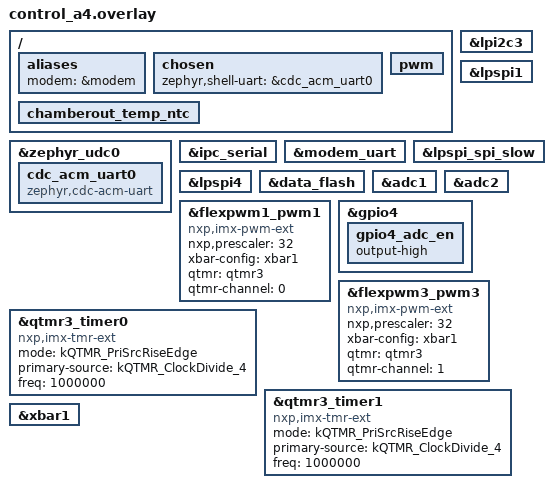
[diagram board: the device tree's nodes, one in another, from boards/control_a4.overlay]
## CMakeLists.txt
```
cmake_minimum_required(VERSION 3.25)

# Must be before find_package(Zephyr) to provide custom board and shield specifications
include(${CMAKE_CURRENT_SOURCE_DIR}/../CMakeFiles/globals.cmake)
include(${CMAKE_CURRENT_SOURCE_DIR}/../CMakeFiles/shields.cmake)

if(NOT DEFINED ENV{ZEPHYR_BASE})
    set(ZEPHYR_BASE ${ZEPHYR_ABS_DIR} CACHE PATH "The directory points to Zephyr root" FORCE)
else()
    set(ZEPHYR_BASE $ENV{ZEPHYR_BASE} CACHE PATH "The directory points to Zephyr root" FORCE)
endif()

if(DEFINED EXTRA_CONF_FILE)
  set(_extra_conf_file_candidates ${EXTRA_CONF_FILE})
  set(_extra_conf_file_existing)

  foreach(_extra_conf_file IN LISTS _extra_conf_file_candidates)
    if(IS_ABSOLUTE "${_extra_conf_file}")
      set(_extra_conf_file_path "${_extra_conf_file}")
    else()
      set(_extra_conf_file_path "${CMAKE_CURRENT_SOURCE_DIR}/${_extra_conf_file}")
    endif()

    if(EXISTS "${_extra_conf_file_path}")
      list(APPEND _extra_conf_file_existing "${_extra_conf_file}")
    else()
      message(STATUS "Skipping missing optional EXTRA_CONF_FILE entry: ${_extra_conf_file}")
    endif()
  endforeach()

  if(_extra_conf_file_existing)
    set(EXTRA_CONF_FILE "${_extra_conf_file_existing}" CACHE STRING "Existing extra configuration files" FORCE)
  else()
    unset(EXTRA_CONF_FILE CACHE)
    unset(EXTRA_CONF_FILE)
  endif()

  unset(_extra_conf_file_candidates)
  unset(_extra_conf_file_existing)
  unset(_extra_conf_file)
  unset(_extra_conf_file_path)
endif()

# Find zephyr and import Zephyr's cmake
find_package(Zephyr REQUIRED HINTS ${ZEPHYR_BASE})

project(control_application)

include(${CMAKE_CURRENT_SOURCE_DIR}/../CMakeFiles/firmware-compile-options.cmake)
include(${PLATFORM_DIR}/CMakeFiles/build-platform-targets.cmake) # Discover all all targets under platform directory.

target_sources(app PRIVATE
  ${CONTROL_SRC_DIR}/main.c
)

generate_inc_file_for_target(
    app
    ${CMAKE_CURRENT_SOURCE_DIR}/one_month.txt
    one_month_txt.inc
)

# Platform units
target_link_libraries(app PRIVATE platform_src_modem_board_obj)
target_link_libraries(app PRIVATE platform_src_modem_at_obj)
target_link_libraries(app PRIVATE platform_src_modem_rc7620_obj)
target_link_libraries(app PRIVATE platform_src_modem_link_obj)
target_link_libraries(app PRIVATE platform_src_modem_shell_obj)

mark_zephyr_system_includes(app)
target_link_libraries(app PRIVATE zephyr_interface)
add_dependencies(app zephyr_generated_headers)
```

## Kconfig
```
source "Kconfig.zephyr"

rsource "../common/Kconfig"

menu "Control application"

config CONTROL_APN
	string "PPP APN"
	default ""
	help
	  APN used by the custom modem PPP shell helpers.

config CONTROL_APN_USERNAME
	string "PPP APN username"
	default ""
	help
	  Optional username used by the custom modem PPP shell helpers.

config CONTROL_APN_PASSWORD
	string "PPP APN password"
	default ""
	help
	  Optional password used by the custom modem PPP shell helpers.

config CONTROL_SERVER_HOST
	string "Verified HTTPS server hostname"
	default ""
	help
	  DNS hostname used for TLS SNI, DNS lookup, and the HTTP Host header
	  when the control application sends its HTTPS upload request.

config CONTROL_SERVER_URL
	string "HTTPS server URL path"
	default "/gus.asmx/dev"
	help
	  HTTP target path used by the control application upload request.

config CONTROL_SERVER_PORT
	int "HTTPS server TCP port"
	range 1 65535
	default 443
	help
	  TCP port used by the control application upload request.

config CONTROL_TLS_SERVER_CA_CERT_PEM
	string "HTTPS POST root CA certificate"
	depends on NET_SOCKETS_SOCKOPT_TLS
	default ""
	help
	  PEM-encoded root CA certificate used by the control application HTTPS
	  upload request. Keep the local-only value in control/prj.secrets.conf
	  and encode line breaks with escaped newlines.

endmenu
```

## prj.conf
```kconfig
#
# Specify project wide configuration of Zephyr for Waitara Control application.
#
# For detailed documentation of Zephyr configuration options, see:
#    https://docs.zephyrproject.org/3.5.0/kconfig.html
# (Ensure version of Zephyr selected matches what is currently in use
#  on project)
#

#
# Select features of Zephyr to be used, these are then further configured in sections below\
#
### Zephyr feature selection ###

CONFIG_CMSIS_RTOS_V2=y                # Use V2 of CMSIS RTOS API required by pRTOS implementation
CONFIG_CONSOLE=y
CONFIG_PICOLIBC=y                     # Use picolibc as C standard library
CONFIG_POLL=y                         # Enable Asynchronous notification framework used in pRTOS

CONFIG_STDOUT_CONSOLE=n               # Redirect STDOUT to a console until proper logging is in place

# Other / Floating Point Services
CONFIG_FPU=y          # Let Zephyr be floating point aware. See https://gitlab.fphcare.com/cpap-software/waitara/waitara/-/issues/432 for additional info
CONFIG_FPU_SHARING=y  # Multiple threads will use floating point operations.


# Custom Linker script 
CONFIG_HAVE_CUSTOM_LINKER_SCRIPT=y # Ensure image is even sized for bootloader 
CONFIG_CUSTOM_LINKER_SCRIPT="linker-script.ld"

### /Zephyr feature selection ###

# Keep RTT log/console enabled (logs on RTT, shell on USB)
CONFIG_USE_SEGGER_RTT=y
CONFIG_SEGGER_RTT_SECTION_NONE=y
CONFIG_RTT_CONSOLE=y
CONFIG_LOG_BACKEND_RTT=y

# Shell over USB CDC ACM
CONFIG_SHELL=y
CONFIG_SHELL_BACKEND_SERIAL=y
CONFIG_SHELL_LOG_BACKEND=n              # Needed to prevent logs from being sent to the shell backend
CONFIG_KERNEL_SHELL=y
CONFIG_SHELL_STACK_SIZE=8192

# USB device stack / CDC ACM
CONFIG_USB_DEVICE_STACK=y
CONFIG_USB_CDC_ACM=y
CONFIG_UART_LINE_CTRL=y
CONFIG_UART_INTERRUPT_DRIVEN=y
CONFIG_USB_DEVICE_INITIALIZE_AT_BOOT=y

# Ensure we can drive board-level USB power enable pins early
CONFIG_GPIO=y
CONFIG_ADC=y

# USB identity
CONFIG_USB_DEVICE_VID=0x2FE3
CONFIG_USB_DEVICE_PID=0x0100
CONFIG_USB_DEVICE_PRODUCT="Modem Control Shell"
CONFIG_USB_DEVICE_MANUFACTURER="FPH"
CONFIG_USB_DEVICE_SN="0000001"

# USB diagnostic logging (enable during bring-up; reduce to WARNING after stable)
CONFIG_USB_DEVICE_LOG_LEVEL_WRN=y
CONFIG_USB_CDC_ACM_LOG_LEVEL_WRN=y

# Use the platform-local RC7620 modem stack.
CONFIG_MODEM=y
CONFIG_MODEM_RC7620=y
CONFIG_PM_DEVICE=y

# Defang periodic AT polling to reduce CMUX contention during PPP data bursts
CONFIG_MODEM_RC7620_PERIODIC_SCRIPT_MS=600000
CONFIG_MODEM_LOG_LEVEL_DBG=n
CONFIG_MODEM_MODULES_LOG_LEVEL_DBG=n
CONFIG_MODEM_CMUX_LOG_LEVEL_DBG=n
CONFIG_MODEM_RC7620_UART_BUFFER_SIZE=2048
CONFIG_MODEM_CMUX_MTU=31
CONFIG_MODEM_CMUX_WORK_BUFFER_SIZE=38
# ISR idle timeout: (UART_BUF/2)/(baud/10)*1000 = (2048/2)/(115200/10)*1000 = 89 ms
CONFIG_MODEM_BACKEND_UART_ISR_RECEIVE_IDLE_TIMEOUT_MS=89

# PPP + networking stack for modem HTTPS POST command
CONFIG_NETWORKING=y
CONFIG_NET_NATIVE=y
CONFIG_NET_L2_PPP=y
CONFIG_NET_L2_PPP_MGMT=y
CONFIG_NET_L2_PPP_OPTION_DNS_USE=y
CONFIG_NET_IPV4=y
CONFIG_NET_IPV6=n
CONFIG_NET_TCP=y
CONFIG_NET_UDP=y
CONFIG_NET_SOCKETS=y
CONFIG_NET_SOCKETS_LOG_LEVEL_DBG=y
CONFIG_POSIX_API=y
CONFIG_DNS_RESOLVER=y
CONFIG_DNS_RESOLVER_LOG_LEVEL_DBG=y
CONFIG_NET_SOCKETS_DNS_TIMEOUT=15000
CONFIG_DNS_RESOLVER_MAX_SERVERS=2
CONFIG_DNS_SERVER_IP_ADDRESSES=y
CONFIG_NET_MGMT=y
CONFIG_NET_MGMT_EVENT=y
CONFIG_NET_CONNECTION_MANAGER=y
CONFIG_NET_L2_PPP_LOG_LEVEL_DBG=y
CONFIG_NET_TX_STACK_SIZE=4096
CONFIG_NET_RX_STACK_SIZE=4096
CONFIG_ZVFS_OPEN_MAX=8
CONFIG_NET_MAX_CONTEXTS=12
CONFIG_NET_SOCKETS_TLS_MAX_CONTEXTS=4

# Network packet buffer pool - default of 4 RX pkts is too low for PPP+DNS
# Match Ethernet default; prevents pool exhaustion during DNS + PPP traffic
CONFIG_NET_PKT_TX_COUNT=16
CONFIG_NET_BUF_TX_COUNT=64
CONFIG_NET_PKT_RX_COUNT=14
# 28 x 128 bytes = 3.5 KB; covers fragmented PPP frames
CONFIG_NET_BUF_RX_COUNT=28
# Keep the TCP send window inside the TX fragment pool used by the known-good upload config.
CONFIG_NET_TCP_MAX_SEND_WINDOW_SIZE=5440
CONFIG_NET_TCP_PKT_ALLOC_TIMEOUT=500

# HTTP client + TLS socket support
CONFIG_HTTP_CLIENT=y
CONFIG_NET_SOCKETS_SOCKOPT_TLS=y

CONFIG_CRYPTO=y
CONFIG_TLS_CREDENTIALS=y
CONFIG_NET_SOCKETS_SOCKOPT_TLS=y
CONFIG_MBEDTLS_PEM_CERTIFICATE_FORMAT=y
CONFIG_MBEDTLS_DEBUG=y

# Buffer/workqueue sizing
CONFIG_USB_CDC_ACM_RINGBUF_SIZE=2048
# Keep the system workqueue responsive during USB IO
# Priority 0 = highest preemptive; prevents CMUX/PPP workqueue starvation
CONFIG_SYSTEM_WORKQUEUE_PRIORITY=3
# 4 KB stack for modem/networking workqueue tasks
CONFIG_SYSTEM_WORKQUEUE_STACK_SIZE=4096
### / Temp for Devboard to P2 board bringup ###

####  RTOS Configuration ###
CONFIG_MAIN_STACK_SIZE=8192
                                        # Match the known-good upload config for HTTPS/TLS request handling and logging
CONFIG_THREAD_NAME=y                    # Allow tracing to display thread name for debugging
CONFIG_THREAD_STACK_INFO=y              # Allow each thread to store thread stack info in k_thread data structure
CONFIG_THREAD_MONITOR=y                 # Instruct kernel to maintain a list of all threads for debugging
CONFIG_THREAD_RUNTIME_STATS=y           # Gather thread runtime statistics. For example: Thread total execution cycles, System total execution cycles. Used for monitoring of scheduler performance
CONFIG_SCHED_THREAD_USAGE=y             # Collect thread runtime usage. Used for monitoring of scheduler performance
CONFIG_INIT_STACKS=y                    # Initialise stacks with a known value so that high water mark can be determined for debugging
                                        # Init value: 0xAA
CONFIG_NUM_COOP_PRIORITIES=2
                                        # Match the known-good upload config used for HTTP client uploads.
CONFIG_PRIORITY_CEILING=0
                                        # If cooperative task is disabled, ceiling priority should be 0, not -127(default)

CONFIG_SYS_CLOCK_TICKS_PER_SEC=10000
                                        # Using value greater than default to increase precision in delays
CONFIG_NUM_PREEMPT_PRIORITIES=56
                                        # Max priority in CMSIS v2. osPriority_t
CONFIG_USERSPACE=n                      # This option ennable threads in user mode to protect kernel
                                        # In current implementation, CMSIS v2 doesn't support options.
CONFIG_HW_STACK_PROTECTION=y            # Catch stack overflows when in privileged mode
CONFIG_STACK_CANARIES=y                 # Inserts a canary value into the stack frame when a function is entered and validates this value upon exit
                                        # Decrease performance. Only for initial state of project.
CONFIG_STACK_CANARIES_ALL=y             # equivalent to GCC option `-fstack-protector-all`
CONFIG_ENTROPY_GENERATOR=y              # CONFIG_STACK_CANARIES dependent option. Used to generate random number for Canary value
CONFIG_NUM_MBOX_ASYNC_MSGS=10
                                        # Default: 10, the total number of asynchronous mailbox messages that can exist simultaneously                                         

# Configuring timeslice size to 1 allows threads on same priority to get execution time every 1 ms. This is
# needed for:
#   - usb_mcx & usbworkq - dependency of device data.
CONFIG_TIMESLICING=y
CONFIG_TIMESLICE_SIZE=1

####  /RTOS Configuration ###

#### CMSIS Configuration ###
CONFIG_CMSIS_V2_THREAD_MAX_STACK_SIZE=8192
                                            # FIXME: Did not think this was required but removing results in run time assertion on dev board
CONFIG_CMSIS_V2_THREAD_DYNAMIC_MAX_COUNT=0
                                            # Define static memory size for dynamic thread in CMSIS
CONFIG_CMSIS_V2_MSGQ_MAX_DYNAMIC_SIZE=0
                                            # Don't allow CMSIS dynamic queues as it violates coding standard

#####
## Following max count is for static memory allocation for OS service in CMSIS V2
## Thread : Only for the number of TCB. Task stack is allocated in Application.
## Queue  : App allocates memory for message and message queue object is allocated from static memory.
## Timer, Mutex, Semaphore, Event : Static memory allocated in CMSIS for these service.
## Memory pool: Fixed size heap. Not needed.
## NOTE : Slap memory internally used in Zephyr is a kind of dynamic memory, but it should be an exception
##        of coding standard. This is an essential feature in zephyr for OS service, such as Queue, Timer,
##        Mutex, Semaphore and Event etc.
####
CONFIG_CMSIS_V2_THREAD_MAX_COUNT=10
                                            # Maximum number of threads, arbitrary value >= current usage
CONFIG_CMSIS_V2_TIMER_MAX_COUNT=10
                                            # Maximum number of timers, arbitrary value >= current usage
CONFIG_CMSIS_V2_EVT_FLAGS_MAX_COUNT=10
                                            # Default: 5, Need to be adjusted later
CONFIG_CMSIS_V2_MSGQ_MAX_COUNT=10
                                            # Default: 5, Memory for message is allocated by App.
                                            #             Memory for message queue is allocated from static
                                            # This max count define max number of message queue.
CONFIG_CMSIS_V2_MUTEX_MAX_COUNT=100
                                            # Default: 5, Need to be adjusted later
CONFIG_CMSIS_V2_SEMAPHORE_MAX_COUNT=20
                                            # Default: 5, Need to be adjusted later
CONFIG_CMSIS_V2_MEM_SLAB_MAX_COUNT=0
CONFIG_CMSIS_V2_MEM_SLAB_MAX_DYNAMIC_SIZE=0
                                            # Fixed size memory pool(similar to heap). No need for waitara
#### /CMSIS Configuration ###

#### Logging and Assertions ####
CONFIG_LOG=y                                # Compile in Zephyr log calls
# Force to y to ensure log output function pointer is valid from `log_format_func_t_get`. Needed for our custom backends if 
# CONFIG_LOG_BACKEND_RTT is not selected.
CONFIG_LOG_OUTPUT=y
CONFIG_LOG_MODE_DEFERRED=y                  # Enables async logging, i.e. processed later by a thread
CONFIG_LOG_PROCESS_THREAD=y                 # Let Zephyr create the logger thread
CONFIG_LOG_PROCESS_THREAD_STARTUP_DELAY_MS=10000
                                            # Adds delay to logging thread startup. Keeping it 10s to allow enough time
                                            # to connect and stream startup logs to Airvolab/Insight.
CONFIG_LOG_PROCESS_THREAD_STACK_SIZE=3072
CONFIG_LOG_PROCESS_THREAD_SLEEP_MS=10
                                            # Flush/Process logs every 10ms
CONFIG_LOG_PROCESS_TRIGGER_THRESHOLD=10
                                            # Threshold at which the buffered log messages are flushed/processed by logging thread.
                                            # Keeping it 10 (default). Since we have 100ms flush, this is an acceptable value.
CONFIG_LOG_BUFFER_SIZE=4096
                                            # Logging internal buffers that will hold the log messages (Keep it reasonably high to avoid losing messages)
CONFIG_LOG_RUNTIME_FILTERING=y              # Enable ability to change log filter level at runtime
CONFIG_LOG_OVERRIDE_LEVEL=0
                                            # Log override is disabled. Anything higher than 1 will cause MPU fault - Data Access Violation.
CONFIG_ASSERT=y                             # Enable asserts within the kernel
CONFIG_ASSERT_LEVEL=2
                                            # Enable asserts but don't warn on files that include __assert.h
CONFIG_LOG_BACKEND_SHOW_COLOR=n             # Disable colour support to avoid special characters appearing in smarttalk bogs
CONFIG_LOG_MODE_OVERFLOW=y                  # Drop the old messages if there is no space left for a new log message
CONFIG_LOG_DEFAULT_LEVEL=3
                                            # Set default log level to INFO to reduce global debug noise
CONFIG_KERNEL_LOG_LEVEL_WRN=y
                                            # Suppress noisy kernel debug traces like z_tick_sleep in RTT
CONFIG_MPU_LOG_LEVEL_WRN=y
                                            # Suppress repetitive MPU debug region programming traces in RTT
CONFIG_INPUT_LOG_LEVEL_WRN=y
                                            # Suppress gpio_keys periodic poll debug traces in RTT

#### Extras
CONFIG_REBOOT=y                       # Enable sys_reboot() API
CONFIG_BUILD_OUTPUT_HEX=y             # Generate Hex output
CONFIG_STD_C17=y                      # Use C17
CONFIG_COMPILER_OPT=""                # Compiler options for Zephyr kernel and project compilation. ex "-O0 -g3 "
CONFIG_KERNEL_BIN_NAME="control_app"  # Can change the output file name
CONFIG_WARN_DEPRECATED=y              # Print a warning when the Kconfig tree is parsed if any deprecated features are enabled.

CONFIG_FLASH=y
CONFIG_SPI_NOR=y                         # spi nor flash for W25Q128JV, JESD216 compatible
CONFIG_FLASH_MAP=y
CONFIG_SPI_NOR_FLASH_LAYOUT_PAGE_SIZE=4096
                                            # This will be block size(default : 65536)
CONFIG_SPI_LOG_LEVEL_ERR=y              # Only set in order to prevent a bug in spi_nxp_lpspi.c causing compilation warnings 
CONFIG_INPUT=y
CONFIG_INPUT_THREAD_STACK_SIZE=2048

# Allows memory manager to make up to 5 attempts to find a chunk
# of the right size to mitigate potential heap fragmentation
CONFIG_SYS_HEAP_ALLOC_LOOPS=5
```

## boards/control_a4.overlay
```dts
/ {
	aliases {
    modem = &modem;
	};

  chosen {
    zephyr,shell-uart = &cdc_acm_uart0;
  };

  pwm {
    status = "okay";
  };

  chamberout_temp_ntc: chamberout_temp_ntc {
    status = "okay";
  };
};

&zephyr_udc0 {
  status = "okay";

  /* Expose CDC ACM as a UART-like device so shell backend can bind to it. */
  cdc_acm_uart0: cdc_acm_uart0 {
    compatible = "zephyr,cdc-acm-uart";
  };
};

&ipc_serial {
  status = "okay";
};

&modem_uart {
  status = "okay";
};

&lpi2c3 {
  status = "okay";
};

&lpspi1 {
  status = "okay";
};

&lpspi_spi_slow {
  status = "okay";
};

&lpspi4 {
  status = "okay";
};

&data_flash {
  status = "okay";
};

&adc1 {
  status = "okay";
};

&adc2 {
  status = "okay";
};

&flexpwm1_pwm1 {
  compatible = "nxp,imx-pwm-ext";
  status = "okay";

  nxp,prescaler = <32>;
  xbar-config = <&xbar1>;
  // See &qtmr3_timer0 node
  qtmr = <&qtmr3>;
  qtmr-channel = <0>;
};

&qtmr3_timer0 {
  compatible = "nxp,imx-tmr-ext";
  status = "okay";

  mode = "kQTMR_PriSrcRiseEdge";
  primary-source = "kQTMR_ClockDivide_4";
  freq = <1000000>;
};

&gpio4 {
  gpio4_adc_en {
    // Enable ADC isolation for control application
    /delete-property/ output-low;
    output-high;
  };
};

&flexpwm3_pwm3 {
  compatible = "nxp,imx-pwm-ext";
  status = "okay";

  nxp,prescaler = <32>;
  xbar-config = <&xbar1>;
  // See &qtmr3_timer1 node
  qtmr = <&qtmr3>;
  qtmr-channel = <1>;
};

&qtmr3_timer1 {
  compatible = "nxp,imx-tmr-ext";
  status = "okay";

  mode = "kQTMR_PriSrcRiseEdge";
  primary-source = "kQTMR_ClockDivide_4";
  freq = <1000000>;
};

&xbar1 {
  status = "okay";
};
```

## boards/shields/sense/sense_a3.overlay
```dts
/*
 * Copyright (c) Fisher & Paykel Healthcare. All Rights Reserved.
 *
 * Devicetree overlay for Waitara Sense A3 shield for the control board. This overlay enables the nodes
 * relevant for the control application.
 */

#include <zephyr/dt-bindings/input/input-event-codes.h>

/ {
  aliases {
    dt-rtc = &rtc;
  };
};

&lpi2c1 {
  status = "okay";
};

&humidity_sensor {
  status = "okay";
};

&rtc {
  status = "okay";
};

&lpi2c4 {
  status = "okay";
};

&pressure_sensor {
  status = "okay";
};

&lpspi3 {
  status = "okay";
};

&ssd1363 {
  status = "okay";
};

&buttons {
  status = "okay";

  polling-mode;
};

&ui_button_therapy_b {
  zephyr,code = <INPUT_BTN_1>;
};

&ui_button_therapy_a {
  zephyr,code = <INPUT_BTN_2>;
};

&ui_button_down {
  zephyr,code = <INPUT_BTN_3>;
};

&ui_button_up {
  zephyr,code = <INPUT_BTN_4>;
};  

&ui_button_ok {
  zephyr,code = <INPUT_BTN_5>;
};  

&ui_button_menu {
  zephyr,code = <INPUT_BTN_6>;
};  

&longpress {
  input-codes = <INPUT_BTN_2>, 
                <INPUT_BTN_1>,
                <INPUT_BTN_3>,
                <INPUT_BTN_4>, 
                <INPUT_BTN_5>, 
                <INPUT_BTN_6>;
  short-codes = <INPUT_KEY_B>, 
                <INPUT_KEY_A>,
                <INPUT_KEY_C>,
                <INPUT_KEY_D>, 
                <INPUT_KEY_E>, 
                <INPUT_KEY_F>;
  long-codes = <INPUT_KEY_V>, 
               <INPUT_KEY_U>,
               <INPUT_KEY_W>,
               <INPUT_KEY_X>, 
               <INPUT_KEY_Y>, 
               <INPUT_KEY_Z>;
  long-delay-ms = <3000>; // 3 second for long press
};
```

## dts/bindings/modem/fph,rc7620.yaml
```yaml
# SPDX-License-Identifier: Apache-2.0

description: FPH RC7620 modem wired for the Waitara control board

compatible: "fph,rc7620"

include: uart-device.yaml

properties:
  mdm-rail-en-gpios:
    type: phandle-array
    required: true

  mdm-pwr-on-gpios:
    type: phandle-array
    required: true

  mdm-reset-gpios:
    type: phandle-array
    required: true

  auto-start:
    type: boolean

  mdm-power-gpios:
    type: phandle-array

  mdm-wake-gpios:
    type: phandle-array
```

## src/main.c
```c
#include <errno.h>
#include <inttypes.h>
#include <stdio.h>
#include <string.h>

#include <zephyr/autoconf.h>
#include <zephyr/kernel.h>
#include <zephyr/logging/log.h>
#include <zephyr/net/conn_mgr_connectivity.h>
#include <zephyr/net/http/client.h>
#include <zephyr/net/net_event.h>
#include <zephyr/net/net_if.h>
#include <zephyr/net/net_ip.h>
#include <zephyr/net/net_mgmt.h>
#include <zephyr/net/ppp.h>
#include <zephyr/net/socket.h>
#include <zephyr/net/tls_credentials.h>

#include "modem-link.h"
#include "../one_month.h"

LOG_MODULE_REGISTER(control_app, LOG_LEVEL_INF);

#define CONTROL_TLS_SEC_TAG 1
#define CONTROL_HTTP_TIMEOUT_MS (180 * MSEC_PER_SEC)
#define CONTROL_HTTP_CHUNK_SIZE 1024U
#define CONTROL_HTTP_RESPONSE_PREVIEW_LEN 160U
#define CONTROL_PPP_CONNECT_TIMEOUT K_SECONDS(MODEM_LINK_DEFAULT_L4_TIMEOUT_MS / 1000)
#define CONTROL_PPP_DISCONNECT_TIMEOUT K_SECONDS(30)
#define CONTROL_PPP_POLL_INTERVAL K_MSEC(250)

struct control_http_context {
    unsigned int http_status_code;
    bool http_status_logged;
    bool response_complete;
    size_t bytes_sent;
    size_t chunks_sent;
    size_t preview_len;
    char response_preview[CONTROL_HTTP_RESPONSE_PREVIEW_LEN + 1U];
};

static K_SEM_DEFINE(controlAppConnectedSem, 0, 1);
static K_SEM_DEFINE(controlAppDisconnectedSem, 0, 1);
static struct net_mgmt_event_callback controlAppNetCbL2;
static struct net_mgmt_event_callback controlAppNetCbL3;
static struct net_mgmt_event_callback controlAppNetCbL4;
static struct net_if *controlAppIface;
static bool controlAppPppRunning;
static bool controlAppIpv4Ready;
static bool controlAppL4Ready;
static bool controlAppDnsReady;

static const char *control_app_net_event_name(uint64_t mgmtEvent)
{
    switch (mgmtEvent) {
    case NET_EVENT_PPP_PHASE_RUNNING:
        return "NET_EVENT_PPP_PHASE_RUNNING";
    case NET_EVENT_IPV4_ADDR_ADD:
        return "NET_EVENT_IPV4_ADDR_ADD";
    case NET_EVENT_DNS_SERVER_ADD:
        return "NET_EVENT_DNS_SERVER_ADD";
    case NET_EVENT_L4_CONNECTED:
        return "NET_EVENT_L4_CONNECTED";
    case NET_EVENT_L4_DISCONNECTED:
        return "NET_EVENT_L4_DISCONNECTED";
    case NET_EVENT_PPP_CARRIER_OFF:
        return "NET_EVENT_PPP_CARRIER_OFF";
    case NET_EVENT_PPP_PHASE_DEAD:
        return "NET_EVENT_PPP_PHASE_DEAD";
    default:
        return "NET_EVENT_UNKNOWN";
    }
}

static void control_app_drain_sem(struct k_sem *sem)
{
    while (k_sem_take(sem, K_NO_WAIT) == 0) {
    }
}

static void control_app_reset_ready_state(void)
{
    controlAppPppRunning = false;
    controlAppIpv4Ready = false;
    controlAppL4Ready = false;
    controlAppDnsReady = false;
}

static void control_app_net_event_handler(struct net_mgmt_event_callback *cb,
                                          uint64_t mgmtEvent,
                                          struct net_if *iface)
{
    ARG_UNUSED(cb);

    if ((controlAppIface != NULL) && (iface != NULL) && (iface != controlAppIface)) {
        return;
    }

    LOG_INF("Network event: %s 0x%" PRIx64,
            control_app_net_event_name(mgmtEvent),
            mgmtEvent);

    switch (mgmtEvent) {
    case NET_EVENT_PPP_PHASE_RUNNING:
        controlAppPppRunning = true;
        break;
    case NET_EVENT_IPV4_ADDR_ADD:
        controlAppIpv4Ready = true;
        break;
    case NET_EVENT_DNS_SERVER_ADD:
        controlAppDnsReady = true;
        break;
    case NET_EVENT_L4_CONNECTED:
        controlAppL4Ready = true;
        break;
    case NET_EVENT_L4_DISCONNECTED:
    case NET_EVENT_PPP_CARRIER_OFF:
    case NET_EVENT_PPP_PHASE_DEAD:
        control_app_reset_ready_state();
        k_sem_give(&controlAppDisconnectedSem);
        return;
    default:
        return;
    }

    if (controlAppPppRunning && (controlAppIpv4Ready || controlAppL4Ready)) {
        if (iface != NULL) {
            net_if_set_default(iface);
        }

        k_sem_give(&controlAppConnectedSem);
    }
}

static void control_app_register_net_events(struct net_if *pppIface)
{
    static bool callbacksRegistered;

    controlAppIface = pppIface;

    if (callbacksRegistered) {
        return;
    }

    net_mgmt_init_event_callback(&controlAppNetCbL2,
                                 control_app_net_event_handler,
                                 NET_EVENT_PPP_PHASE_RUNNING |
                                 NET_EVENT_PPP_CARRIER_OFF |
                                 NET_EVENT_PPP_PHASE_DEAD);
    net_mgmt_add_event_callback(&controlAppNetCbL2);

    net_mgmt_init_event_callback(&controlAppNetCbL3,
                                 control_app_net_event_handler,
                                 NET_EVENT_IPV4_ADDR_ADD |
                                 NET_EVENT_DNS_SERVER_ADD);
    net_mgmt_add_event_callback(&controlAppNetCbL3);

    net_mgmt_init_event_callback(&controlAppNetCbL4,
                                 control_app_net_event_handler,
                                 NET_EVENT_L4_CONNECTED |
                                 NET_EVENT_L4_DISCONNECTED);
    net_mgmt_add_event_callback(&controlAppNetCbL4);

    callbacksRegistered = true;
}

static int control_app_connect_ppp(struct net_if *pppIface)
{
    int ret;

    control_app_reset_ready_state();
    control_app_drain_sem(&controlAppConnectedSem);

    ret = conn_mgr_if_connect(pppIface);
    if (ret != 0) {
        LOG_ERR("conn_mgr_if_connect failed: %d", ret);
        return ret;
    }

    LOG_INF("Waiting for PPP ready event...");
    ret = k_sem_take(&controlAppConnectedSem, CONTROL_PPP_CONNECT_TIMEOUT);
    if (ret != 0) {
        LOG_ERR("Timed out waiting for PPP ready event: %d", ret);
        return ret;
    }

    LOG_INF("PPP connected");
    return 0;
}

static int control_app_disconnect_ppp(struct net_if *pppIface)
{
    int ret;

    control_app_drain_sem(&controlAppDisconnectedSem);

    ret = conn_mgr_if_disconnect(pppIface);
    if (ret != 0) {
        LOG_ERR("conn_mgr_if_disconnect failed: %d", ret);
        return ret;
    }

    LOG_INF("Waiting for PPP teardown event...");
    ret = k_sem_take(&controlAppDisconnectedSem, CONTROL_PPP_DISCONNECT_TIMEOUT);
    if (ret != 0) {
        LOG_ERR("Timed out waiting for PPP teardown: %d", ret);
        return ret;
    }

    LOG_INF("PPP disconnected");
    return 0;
}

static bool control_app_http_status_is_success(unsigned int status_code)
{
    return (status_code >= 200U) && (status_code < 300U);
}

static void control_app_append_response_preview(struct control_http_context *context,
                                                const uint8_t *fragment,
                                                size_t fragment_len)
{
    size_t idx;

    if ((context == NULL) || (fragment == NULL) || (fragment_len == 0U)) {
        return;
    }

    for (idx = 0U; idx < fragment_len; idx++) {
        const uint8_t ch = fragment[idx];

        if (context->preview_len >= CONTROL_HTTP_RESPONSE_PREVIEW_LEN) {
            break;
        }

        if ((ch >= 0x20U) && (ch <= 0x7eU)) {
            context->response_preview[context->preview_len++] = (char)ch;
        } else if ((ch == '\n') || (ch == '\r') || (ch == '\t')) {
            context->response_preview[context->preview_len++] = ' ';
        } else {
            context->response_preview[context->preview_len++] = '.';
        }
    }

    context->response_preview[context->preview_len] = '\0';
}

static size_t control_app_normalize_pem_string(const char *src,
                                               char *dst,
                                               size_t dst_size)
{
    size_t src_idx = 0U;
    size_t dst_idx = 0U;

    while ((src[src_idx] != '\0') && (dst_idx + 1U < dst_size)) {
        if (src[src_idx] == '\\') {
            if ((src[src_idx + 1U] == '\\') && (src[src_idx + 2U] != '\0')) {
                switch (src[src_idx + 2U]) {
                case 'n':
                    dst[dst_idx++] = '\n';
                    src_idx += 3U;
                    continue;
                case 'r':
                    dst[dst_idx++] = '\r';
                    src_idx += 3U;
                    continue;
                case 't':
                    dst[dst_idx++] = '\t';
                    src_idx += 3U;
                    continue;
                default:
                    break;
                }
            }

            if (src[src_idx + 1U] != '\0') {
                switch (src[src_idx + 1U]) {
                case 'n':
                    dst[dst_idx++] = '\n';
                    src_idx += 2U;
                    continue;
                case 'r':
                    dst[dst_idx++] = '\r';
                    src_idx += 2U;
                    continue;
                case 't':
                    dst[dst_idx++] = '\t';
                    src_idx += 2U;
                    continue;
                case '\\':
                    dst[dst_idx++] = '\\';
                    src_idx += 2U;
                    continue;
                default:
                    break;
                }
            }
        }

        dst[dst_idx++] = src[src_idx++];
    }

    dst[dst_idx] = '\0';
    return dst_idx;
}

static int control_app_tls_setup(void)
{
    static bool tls_credential_added;
    static char ca_cert_pem[sizeof(CONFIG_CONTROL_TLS_SERVER_CA_CERT_PEM)];
    size_t normalized_len;
    int ret;

    if (tls_credential_added) {
        return 0;
    }

    if (strlen(CONFIG_CONTROL_TLS_SERVER_CA_CERT_PEM) == 0U) {
        LOG_ERR("TLS certificate empty");
        return -EINVAL;
    }

    normalized_len = control_app_normalize_pem_string(CONFIG_CONTROL_TLS_SERVER_CA_CERT_PEM,
                                                      ca_cert_pem,
                                                      sizeof(ca_cert_pem));
    if (normalized_len == 0U) {
        LOG_ERR("PEM normalization failed");
        return -EINVAL;
    }

    ret = tls_credential_add(CONTROL_TLS_SEC_TAG,
                             TLS_CREDENTIAL_CA_CERTIFICATE,
                             ca_cert_pem,
                             normalized_len + 1U);
    if ((ret < 0) && (ret != -EEXIST)) {
        LOG_ERR("tls_credential_add failed: %d", ret);
        return ret;
    }

    tls_credential_added = true;
    return 0;
}

static int control_app_configure_tls_socket(int sock, const char *server_host)
{
    sec_tag_t sec_tag_list[] = { CONTROL_TLS_SEC_TAG };
    const int verify = TLS_PEER_VERIFY_REQUIRED;
    const struct timeval recv_timeout = {
        .tv_sec = CONTROL_HTTP_TIMEOUT_MS / MSEC_PER_SEC,
        .tv_usec = 0,
    };
    int ret;

    ret = zsock_setsockopt(sock, SOL_TLS, TLS_SEC_TAG_LIST,
                           sec_tag_list, sizeof(sec_tag_list));
    if (ret < 0) {
        return -errno;
    }

    ret = zsock_setsockopt(sock, SOL_TLS, TLS_HOSTNAME,
                           server_host, strlen(server_host));
    if (ret < 0) {
        return -errno;
    }

    ret = zsock_setsockopt(sock, SOL_TLS, TLS_PEER_VERIFY,
                           &verify, sizeof(verify));
    if (ret < 0) {
        return -errno;
    }

    ret = zsock_setsockopt(sock, SOL_SOCKET, SO_RCVTIMEO,
                           &recv_timeout, sizeof(recv_timeout));
    if (ret < 0) {
        return -errno;
    }

    return 0;
}

static int control_app_response_cb(struct http_response *rsp,
                                   enum http_final_call final_data,
                                   void *user_data)
{
    struct control_http_context *context = user_data;

    if ((rsp == NULL) || (context == NULL)) {
        return -EINVAL;
    }

    context->http_status_code = rsp->http_status_code;

    if ((rsp->http_status_code > 0U) && !context->http_status_logged) {
        LOG_INF("HTTP status: %u %s",
                (unsigned int)rsp->http_status_code,
                rsp->http_status);
        context->http_status_logged = true;
    }

    if ((rsp->body_frag_start != NULL) && (rsp->body_frag_len > 0U)) {
        control_app_append_response_preview(context,
                                            rsp->body_frag_start,
                                            rsp->body_frag_len);
    }

    if (final_data == HTTP_DATA_MORE) {
        LOG_INF("HTTP response progress: processed=%u body=%u bytes",
                (unsigned int)rsp->processed,
                (unsigned int)rsp->body_frag_len);
    }

    if (final_data == HTTP_DATA_FINAL) {
        context->response_complete = true;
        LOG_INF("HTTP response complete: processed=%u bytes",
                (unsigned int)rsp->processed);

        if (context->preview_len > 0U) {
            LOG_INF("HTTP response preview: %s", context->response_preview);
        }
    }

    return 0;
}

static int control_app_send_buffer_with_retry(int sock, const void *buffer, size_t length)
{
    const uint8_t *data = buffer;
    size_t offset = 0U;

    while (offset < length) {
        const ssize_t ret = zsock_send(sock, data + offset, length - offset, 0);

        if (ret > 0) {
            offset += (size_t)ret;
            LOG_INF("============== PARTIAL : %d , length : %d, offset: %d ============================",
                    (int)ret,
                    (int)length,
                    (int)offset);
            continue;
        }

        if ((ret < 0) && ((errno == EAGAIN) || (errno == ENOMEM))) {
            k_sleep(K_MSEC(5));
            LOG_INF("++++++++++++++++RETRY++++++++++++++++++++++");
            continue;
        }

        return (ret < 0) ? -errno : -EIO;
    }

    return 0;
}

static int control_app_payload_cb(int sock, struct http_request *req, void *user_data)
{
    struct control_http_context *context = user_data;
    static uint8_t chunk_buffer[CONTROL_HTTP_CHUNK_SIZE + 16U];
    size_t offset = 0U;
    unsigned int last_logged_pct = 0U;
    int total_sent = 0;

    ARG_UNUSED(req);

    LOG_INF("HTTP upload: %u bytes, chunk_size=%u",
            (unsigned int)ONE_MONTH_DATA_SIZE,
            (unsigned int)CONTROL_HTTP_CHUNK_SIZE);

    while (offset < ONE_MONTH_DATA_SIZE) {
        const size_t chunk_size = MIN(CONTROL_HTTP_CHUNK_SIZE, ONE_MONTH_DATA_SIZE - offset);
        const int header_len = snprintk((char *)chunk_buffer,
                                        sizeof(chunk_buffer),
                                        "%zx\r\n",
                                        chunk_size);
        const size_t chunk_total = (size_t)header_len + chunk_size + 2U;
        unsigned int pct;
        int ret;

        if ((header_len <= 0) || (chunk_total > sizeof(chunk_buffer))) {
            return -ENOMEM;
        }

        memcpy(&chunk_buffer[header_len], one_month_data + offset, chunk_size);
        chunk_buffer[header_len + chunk_size] = '\r';
        chunk_buffer[header_len + chunk_size + 1U] = '\n';

        LOG_INF("Sending chunk: payload_offset=%u payload_len=%u wire_len=%u",
                (unsigned int)offset,
                (unsigned int)chunk_size,
                (unsigned int)chunk_total);

        ret = control_app_send_buffer_with_retry(sock, chunk_buffer, chunk_total);
        if (ret < 0) {
            LOG_ERR("Failed to send chunk at offset %u: %d",
                    (unsigned int)offset,
                    ret);
            return ret;
        }

        offset += chunk_size;
        total_sent += (int)chunk_total;

        if (context != NULL) {
            context->bytes_sent = offset;
            context->chunks_sent++;
        }

        pct = (unsigned int)((offset * 100U) / ONE_MONTH_DATA_SIZE);
        if ((offset == ONE_MONTH_DATA_SIZE) || ((pct / 25U) > (last_logged_pct / 25U))) {
            LOG_INF("Upload progress: %u/%u bytes (%u%%), chunk %u",
                    (unsigned int)offset,
                    (unsigned int)ONE_MONTH_DATA_SIZE,
                    pct,
                    (unsigned int)((context != NULL) ? context->chunks_sent : 0U));
            last_logged_pct = pct;
        }
    }

    {
        LOG_INF("Sending final chunk terminator");
        const int ret = control_app_send_buffer_with_retry(sock, "0\r\n\r\n", 5U);

        if (ret < 0) {
            LOG_ERR("Failed to send final chunk terminator");
            return ret;
        }
    }

    LOG_INF("Chunked payload transmission complete: %u chunks, %u payload bytes",
            (unsigned int)((context != NULL) ? context->chunks_sent : 0U),
            (unsigned int)ONE_MONTH_DATA_SIZE);

    return total_sent + 5;
}

static int control_app_send_https_upload(void)
{
    const char *server_host = CONFIG_CONTROL_SERVER_HOST;
    const char *server_url = CONFIG_CONTROL_SERVER_URL;
    const char *headers[] = {
        "Transfer-Encoding: chunked\r\n",
        "Connection: close\r\n",
        NULL,
    };
    struct zsock_addrinfo hints = {
        .ai_family = AF_INET,
        .ai_socktype = SOCK_STREAM,
    };
    struct zsock_addrinfo *res = NULL;
    struct http_request req = { 0 };
    struct control_http_context context = { 0 };
    uint8_t rx_buf[512];
    char port[6];
    int64_t connect_start_ms;
    int64_t connect_elapsed_ms;
    int64_t request_start_ms;
    int64_t request_elapsed_ms;
    int sock = -1;
    int ret;

    if ((strlen(server_host) == 0U) || (strlen(server_url) == 0U)) {
        LOG_ERR("Server configuration incomplete");
        return -EINVAL;
    }

    ret = control_app_tls_setup();
    if (ret < 0) {
        return ret;
    }

    ret = snprintf(port, sizeof(port), "%d", CONFIG_CONTROL_SERVER_PORT);
    if ((ret <= 0) || (ret >= (int)sizeof(port))) {
        return -EINVAL;
    }

    LOG_INF("HTTPS upload target: %s:%s%s", server_host, port, server_url);
    LOG_INF("Payload size: %u bytes", (unsigned int)ONE_MONTH_DATA_SIZE);
    LOG_INF("HTTP upload mode: chunked payload callback (%u-byte chunks)",
        (unsigned int)CONTROL_HTTP_CHUNK_SIZE);

    ret = zsock_getaddrinfo(server_host, port, &hints, &res);
    if (ret != 0) {
        LOG_ERR("DNS lookup failed: %d", ret);
        return -EHOSTUNREACH;
    }

    sock = zsock_socket(res->ai_family, res->ai_socktype, IPPROTO_TLS_1_2);
    if (sock < 0) {
        ret = -errno;
        zsock_freeaddrinfo(res);
        return ret;
    }

    ret = control_app_configure_tls_socket(sock, server_host);
    if (ret < 0) {
        zsock_close(sock);
        zsock_freeaddrinfo(res);
        return ret;
    }

    connect_start_ms = k_uptime_get();
    ret = zsock_connect(sock, res->ai_addr, res->ai_addrlen);
    connect_elapsed_ms = k_uptime_get() - connect_start_ms;
    zsock_freeaddrinfo(res);
    if (ret < 0) {
        ret = -errno;
        zsock_close(sock);
        return ret;
    }

    LOG_INF("TLS connect complete in %lld ms", connect_elapsed_ms);

    req.method = HTTP_POST;
    req.url = server_url;
    req.protocol = "HTTP/1.1";
    req.host = server_host;
    req.header_fields = headers;
    req.content_type_value = "application/octet-stream";
    req.payload_cb = control_app_payload_cb;
    req.payload = NULL;
    req.payload_len = 0U;
    req.response = control_app_response_cb;
    req.recv_buf = rx_buf;
    req.recv_buf_len = sizeof(rx_buf);

        LOG_INF("HTTP POST request: %s, chunked payload=%u bytes, chunk_size=%u, rx_buf=%u bytes",
            server_url,
            (unsigned int)ONE_MONTH_DATA_SIZE,
            (unsigned int)CONTROL_HTTP_CHUNK_SIZE,
            (unsigned int)sizeof(rx_buf));

    request_start_ms = k_uptime_get();
    ret = http_client_req(sock, &req, CONTROL_HTTP_TIMEOUT_MS, &context);
    request_elapsed_ms = k_uptime_get() - request_start_ms;
    zsock_close(sock);
    if (ret < 0) {
        LOG_ERR("Upload failure stats: sent=%u payload bytes across %u chunks",
                (unsigned int)context.bytes_sent,
                (unsigned int)context.chunks_sent);
        LOG_ERR("http_client_req failed after %lld ms: %d", request_elapsed_ms, ret);
        return ret;
    }

    if (!context.response_complete) {
        return -EBADMSG;
    }

    LOG_INF("HTTP upload sent %u on-wire bytes in %lld ms",
            (unsigned int)ret,
            request_elapsed_ms);
    LOG_INF("HTTP upload payload bytes: %u across %u chunks",
            (unsigned int)context.bytes_sent,
            (unsigned int)context.chunks_sent);

    if (request_elapsed_ms > 0) {
        const uint64_t bytes_per_sec = ((uint64_t)context.bytes_sent * 1000U) /
                                       (uint64_t)request_elapsed_ms;
        LOG_INF("HTTP upload payload throughput: %llu B/s", bytes_per_sec);
    }

    if (!control_app_http_status_is_success(context.http_status_code)) {
        LOG_ERR("Upload returned non-2xx status: %u", context.http_status_code);
        return -EBADMSG;
    }

    LOG_INF("Upload status: %u", context.http_status_code);
    return 0;
}

static void control_app_log_ipv4_address(struct net_if *iface)
{
    const struct in_addr *address;
    char buffer[NET_IPV4_ADDR_LEN];

    address = net_if_ipv4_get_global_addr(iface, NET_ADDR_PREFERRED);
    if (address == NULL) {
        LOG_WRN("No IPv4 address assigned yet");
        return;
    }

    if (net_addr_ntop(AF_INET, address, buffer, sizeof(buffer)) == NULL) {
        LOG_WRN("Failed to format IPv4 address");
        return;
    }

    LOG_INF("PPP IPv4 address: %s", buffer);
}

int main(void)
{
    struct net_if *pppIface = NULL;
    unsigned int cycle;
    int ret;

    LOG_INF("Control app boot: connecting through conn_mgr");

    ret = modem_link_get_ppp_iface(&pppIface);
    if ((ret != 0) || (pppIface == NULL)) {
        LOG_ERR("PPP iface lookup failed: %d", ret);
        return 0;
    }

    control_app_register_net_events(pppIface);

    ret = conn_mgr_if_set_timeout(pppIface, MODEM_LINK_DEFAULT_L4_TIMEOUT_MS / MSEC_PER_SEC);
    if (ret != 0) {
        LOG_WRN("conn_mgr_if_set_timeout failed: %d", ret);
    }

    for (cycle = 1U; cycle <= 2U; cycle++) {
        if (cycle > 1U) {
            LOG_INF("=========== %uth connection ===================", cycle);
        }

        ret = control_app_connect_ppp(pppIface);
        if (ret != 0) {
            return 0;
        }

        control_app_log_ipv4_address(pppIface);
        net_if_set_default(pppIface);

        ret = control_app_send_https_upload();
        if (ret != 0) {
            LOG_ERR("HTTPS upload failed: %d", ret);
        }

        ret = control_app_disconnect_ppp(pppIface);
        if (ret != 0) {
            return 0;
        }
    }

    while (1) {
        k_sleep(K_FOREVER);
    }
}
```

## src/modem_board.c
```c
#include "modem_board.h"

#include <zephyr/device.h>
#include <zephyr/devicetree.h>
#include <zephyr/drivers/gpio.h>
#include <zephyr/logging/log.h>

LOG_MODULE_REGISTER(modem_board, LOG_LEVEL_INF);

#define MODEM_NODE DT_PATH(zephyr_user)

#if !DT_NODE_HAS_PROP(MODEM_NODE, modem_3v8_en_gpios)
#error "Missing /zephyr,user modem-3v8-en-gpios devicetree property"
#endif
#if !DT_NODE_HAS_PROP(MODEM_NODE, modem_pwr_on_n_gpios)
#error "Missing /zephyr,user modem-pwr-on-n-gpios devicetree property"
#endif
#if !DT_NODE_HAS_PROP(MODEM_NODE, modem_nrst_n_gpios)
#error "Missing /zephyr,user modem-nrst-n-gpios devicetree property"
#endif

static const struct gpio_dt_spec rail_en = GPIO_DT_SPEC_GET(MODEM_NODE, modem_3v8_en_gpios);
static const struct gpio_dt_spec pwr_on_n = GPIO_DT_SPEC_GET(MODEM_NODE, modem_pwr_on_n_gpios);
static const struct gpio_dt_spec nrst_n = GPIO_DT_SPEC_GET(MODEM_NODE, modem_nrst_n_gpios);

/*
 * NOTE: Exact modem timing requirements need to be confirmed.
 * These defaults are based on common cellular modem patterns.
 */
static const k_timeout_t T_RAIL_SETTLE = K_MSEC(10);
static const k_timeout_t T_PWR_ON_PULSE = K_MSEC(250);
static const k_timeout_t T_PWR_OFF_PULSE = K_MSEC(1500);
static const k_timeout_t T_POST_ON_DELAY = K_MSEC(100);
static const k_timeout_t T_RESET_PULSE = K_MSEC(200);

int modem_board_init(void)
{
	if (!device_is_ready(rail_en.port)) {
		LOG_ERR("rail_en gpio port not ready");
		return -ENODEV;
	}
	if (!device_is_ready(pwr_on_n.port)) {
		LOG_ERR("pwr_on_n gpio port not ready");
		return -ENODEV;
	}
	if (!device_is_ready(nrst_n.port)) {
		LOG_ERR("nrst_n gpio port not ready");
		return -ENODEV;
	}

	/* Default safe state: rail off, PWR_ON_N deasserted, reset asserted (if already configured). */
	int ret;

	ret = gpio_pin_configure_dt(&rail_en, GPIO_OUTPUT_INACTIVE);
	if (ret != 0) {
		LOG_ERR("Failed to configure rail_en: %d", ret);
		return ret;
	}

	ret = gpio_pin_configure_dt(&pwr_on_n, GPIO_OUTPUT_INACTIVE);
	if (ret != 0) {
		LOG_ERR("Failed to configure pwr_on_n: %d", ret);
		return ret;
	}

	/* nrst_n may be configured by a gpio-hog on this board; just drive it to asserted state. */
	(void)gpio_pin_set_dt(&nrst_n, 1);

	return 0;
}

static int pwr_on_n_pulse(k_timeout_t pulse)
{
	int ret;
	ret = gpio_pin_set_dt(&pwr_on_n, 1); /* assert (active low) */
	if (ret != 0) {
		return ret;
	}
	k_sleep(pulse);
	ret = gpio_pin_set_dt(&pwr_on_n, 0); /* deassert */
	return ret;
}

int modem_board_power_on(void)
{
	int ret;

	/* Assert reset while sequencing power. */
	(void)gpio_pin_set_dt(&nrst_n, 1);

	ret = gpio_pin_set_dt(&rail_en, 1);
	if (ret != 0) {
		return ret;
	}
	k_sleep(T_RAIL_SETTLE);

	ret = pwr_on_n_pulse(T_PWR_ON_PULSE);
	if (ret != 0) {
		return ret;
	}

	k_sleep(T_POST_ON_DELAY);
	/* Release reset */
	ret = gpio_pin_set_dt(&nrst_n, 0);
	return ret;
}

int modem_board_power_off(void)
{
	int ret;

	/* Optionally request modem shutdown via long PWR_ON_N pulse. */
	ret = pwr_on_n_pulse(T_PWR_OFF_PULSE);
	if (ret != 0) {
		return ret;
	}

	/* Assert reset, then remove rail. */
	(void)gpio_pin_set_dt(&nrst_n, 1);
	k_sleep(K_MSEC(20));
	ret = gpio_pin_set_dt(&rail_en, 0);
	return ret;
}

int modem_board_power_cycle(void)
{
	int ret;
	ret = modem_board_power_off();
	if (ret != 0) {
		return ret;
	}
	k_sleep(K_MSEC(500));
	return modem_board_power_on();
}

int modem_board_reset_pulse(void)
{
	int ret;
	ret = gpio_pin_set_dt(&nrst_n, 1);
	if (ret != 0) {
		return ret;
	}
	k_sleep(T_RESET_PULSE);
	ret = gpio_pin_set_dt(&nrst_n, 0);
	return ret;
}

void modem_board_status_print(void)
{
	int rail = gpio_pin_get_dt(&rail_en);
	int pwr = gpio_pin_get_dt(&pwr_on_n);
	int rst = gpio_pin_get_dt(&nrst_n);

	LOG_INF("MODEM_3V8_EN=%d, MODEM_PWR_ON_N=%d, MODEM_nRST=%d", rail, pwr, rst);
}

static int modem_board_sys_init(void)
{
	int ret = modem_board_init();
	if (ret != 0) {
		LOG_ERR("modem_board_init failed: %d", ret);
	}
	return ret;
}

SYS_INIT(modem_board_sys_init, POST_KERNEL, CONFIG_KERNEL_INIT_PRIORITY_DEFAULT);
```

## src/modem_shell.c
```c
#include "modem_board.h"

#include <errno.h>
#include <string.h>

#include <zephyr/shell/shell.h>

static int cmd_modem_status(const struct shell *sh, size_t argc, char **argv)
{
	ARG_UNUSED(argc);
	ARG_UNUSED(argv);

	modem_board_status_print();
	shell_print(sh, "OK");
	return 0;
}

static int cmd_modem_reset(const struct shell *sh, size_t argc, char **argv)
{
	ARG_UNUSED(argc);
	ARG_UNUSED(argv);

	int ret = modem_board_reset_pulse();
	if (ret != 0) {
		shell_error(sh, "reset failed: %d", ret);
		return ret;
	}

	shell_print(sh, "OK");
	return 0;
}

static int cmd_modem_power(const struct shell *sh, size_t argc, char **argv)
{
	if (argc < 2) {
		shell_error(sh, "usage: modem power <on|off|cycle>");
		return -EINVAL;
	}

	const char *op = argv[1];
	int ret = 0;

	if (strcmp(op, "on") == 0) {
		ret = modem_board_power_on();
	} else if (strcmp(op, "off") == 0) {
		ret = modem_board_power_off();
	} else if (strcmp(op, "cycle") == 0) {
		ret = modem_board_power_cycle();
	} else {
		shell_error(sh, "unknown power op: %s", op);
		return -EINVAL;
	}

	if (ret != 0) {
		shell_error(sh, "power %s failed: %d", op, ret);
		return ret;
	}

	shell_print(sh, "OK");
	return 0;
}

SHELL_STATIC_SUBCMD_SET_CREATE(sub_modem,
	SHELL_CMD(status, NULL, "Print modem GPIO status", cmd_modem_status),
	SHELL_CMD(reset, NULL, "Pulse modem reset (MODEM_nRST)", cmd_modem_reset),
	SHELL_CMD_ARG(power, NULL, "Modem power control: power <on|off|cycle>", cmd_modem_power, 2, 0),
	SHELL_SUBCMD_SET_END /* Array terminator */
);

SHELL_CMD_REGISTER(modem, &sub_modem, "Modem control", NULL);
```
